# m52363b register map
Vendor: Elmos Semiconductor SE; Series: Integrated Driver; File version: 1.0
CPU: CM23 r1p0, little endian, MPU, no FPU, VTOR, 2 interrupt priority bits, 13 interrupts
Registers are 16-bit, read-write, reset 0x0 unless marked. A register's access mark holds for its fields unless they carry their own. Offsets are from the block's base; [hi:lo] are bit positions; {n}, {i} and the like mark numbered series; 'fields as' and 'values as' point back to an identical list.

## HB — Half bridge control module
Base 0x50000200
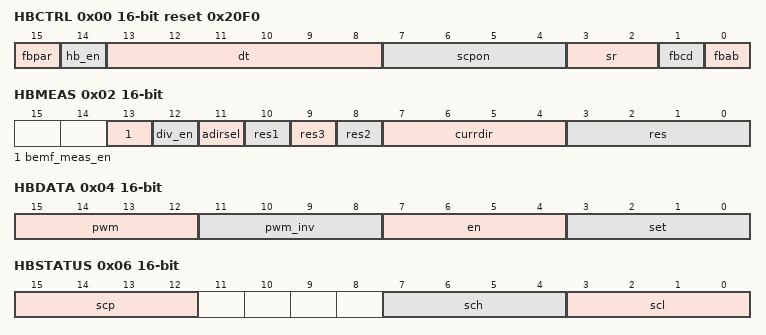
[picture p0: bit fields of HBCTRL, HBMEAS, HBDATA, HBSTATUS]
0x00 HBCTRL reset 0x20F0
  [15] fbpar — fbpar bitfield
  [14] hb_en — hb_en bitfield
  [13:8] dt — dt bitfield
  [7:4] scpon — scpon bitfield
  [3:2] sr — sr bitfield
  [1] fbcd — fbcd bitfield
  [0] fbab — fbab bitfield
0x02 HBMEAS
  [13] bemf_meas_en — bemf_meas_en bitfield
  [12] div_en — div_en bitfield
  [11] adirsel — adirsel bitfield
  [10] res1 — res1 bitfield
  [9] res3 — res3 bitfield
  [8] res2 — res2 bitfield
  [7:4] currdir ro — currdir bitfield
  [3:0] res — res bitfield
0x04 HBDATA
  [15:12] pwm — pwm bitfield
  [11:8] pwm_inv — pwm_inv bitfield
  [7:4] en — en bitfield
  [3:0] set — set bitfield
0x06 HBSTATUS
  [15:12] scp — scp bitfield
  [7:4] sch — sch bitfield
  [3:0] scl — scl bitfield
0x0A HBSCPTMR reset 0x7FF
  [11:0] sc_tmr_val — sc_tmr_val bitfield
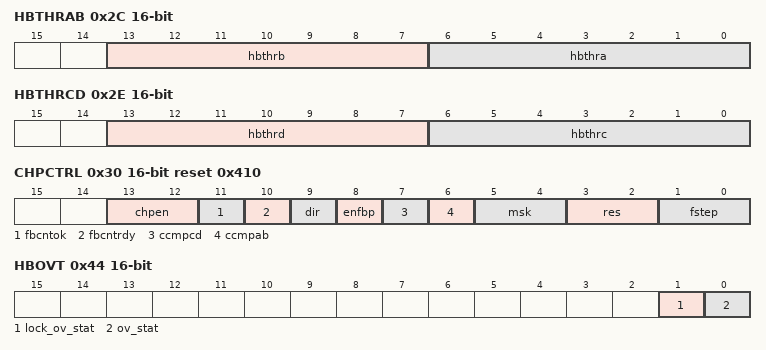
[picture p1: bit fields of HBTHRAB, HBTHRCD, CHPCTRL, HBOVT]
0x2C HBTHRAB
  [13:7] hbthrb — hbthrb bitfield
  [6:0] hbthra — hbthra bitfield
0x2E HBTHRCD
  [13:7] hbthrd — hbthrd bitfield
  [6:0] hbthrc — hbthrc bitfield
0x30 CHPCTRL reset 0x410
  [13:12] chpen — chpen bitfield
  [11] fbcntok ro — fbcntok bitfield
  [10] fbcntrdy ro — fbcntrdy bitfield
  [9] dir — dir bitfield
  [8] enfbp — enfbp bitfield
  [7] ccmpcd ro — ccmpcd bitfield
  [6] ccmpab ro — ccmpab bitfield
  [5:4] msk — msk bitfield
  [3:2] res — res bitfield
  [1:0] fstep — fstep bitfield
0x32 STPCTRL
  [0] stp — stp bitfield
0x34 IDACAB reset 0x1
  [7:0] val — val bitfield
0x36 IDACCD reset 0x1
  [7:0] val — val bitfield
0x38 TONAB ro
  [10:0] val — val bitfield
0x3A TONCD ro
  [10:0] val — val bitfield
0x3C FDEC reset 0x1
  [10:0] val — val bitfield
0x3E CNTFBC ro
  [6:0] val — val bitfield
0x40 HBCTRL1
  [3:0] ds_fasten — ds_fasten bitfield
0x44 HBOVT
  [1] lock_ov_stat — lock_ov_stat bitfield
  [0] ov_stat — ov_stat bitfield
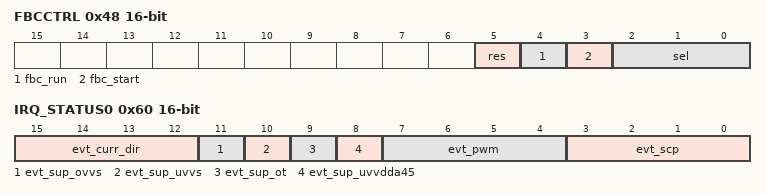
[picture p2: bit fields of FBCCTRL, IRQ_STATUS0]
0x48 FBCCTRL
  [5] res — res bitfield
  [4] fbc_run ro — fbc_run bitfield
  [3] fbc_start — fbc_start bitfield
  [2:0] sel — sel bitfield
0x60 IRQ_STATUS0
  [15:12] evt_curr_dir — evt_curr_dir bitfield
  [11] evt_sup_ovvs — evt_sup_ovvs bitfield
  [10] evt_sup_uvvs — evt_sup_uvvs bitfield
  [9] evt_sup_ot — evt_sup_ot bitfield
  [8] evt_sup_uvvdda45 — evt_sup_uvvdda45 bitfield
  [7:4] evt_pwm — evt_pwm bitfield
  [3:0] evt_scp — evt_scp bitfield
0x62 IRQ_STATUS1
  [0] evt_fbc_rdy — evt_fbc_rdy bitfield
0x64 IRQ_MASK0
  [15:0] mask — mask bitfield
0x66 IRQ_MASK1
  [0] mask — mask bitfield
0x68 IRQ_VENABLE wo reset not defined
  [4:0] vno — vno bitfield
0x6A IRQ_VDISABLE wo reset not defined
  [4:0] vno — vno bitfield
0x6C IRQ_VMAX reset 0x11
  [4:0] vmax — vmax bitfield
0x6E IRQ_VNO reset 0x11
  [4:0] vno — vno bitfield

## PWM — PWM module for half bridge control
Base 0x50000300
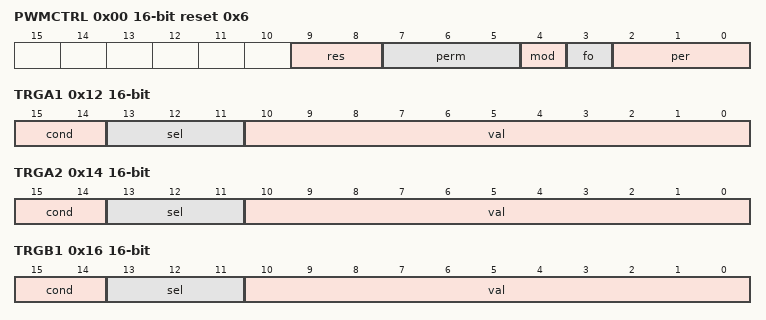
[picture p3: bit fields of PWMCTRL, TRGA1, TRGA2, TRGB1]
0x00 PWMCTRL reset 0x6
  [9:8] res — res bitfield
  [7:5] perm — perm bitfield
  [4] mod — mod bitfield
  [3] fo — fo bitfield
  [2:0] per — per bitfield
0x02 PWMVALA
  [15:5] val — val bitfield
0x04 PWMVALB
  [15:5] val — val bitfield
0x06 PWMVALC
  [15:5] val — val bitfield
0x08 PWMVALD
  [15:5] val — val bitfield
0x0A PWMSHIFTA
  [10:0] val — val bitfield
0x0C PWMSHIFTB
  [10:0] val — val bitfield
0x0E PWMSHIFTC
  [10:0] val — val bitfield
0x10 PWMSHIFTD
  [10:0] val — val bitfield
0x12 TRGA1
  [15:14] cond — cond bitfield
  [13:11] sel — sel bitfield
  [10:0] val — val bitfield
0x14 TRGA2
  fields as TRGA1
0x16 TRGB1
  fields as TRGA1
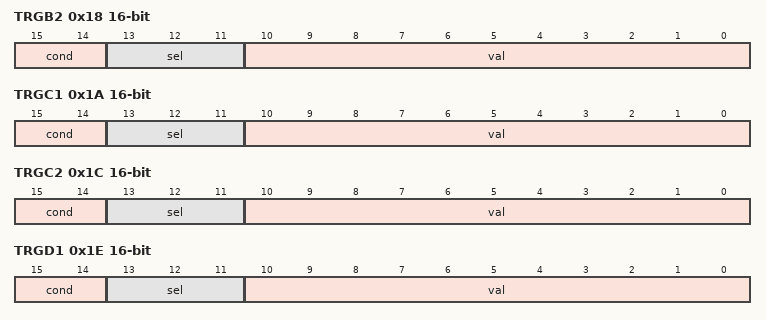
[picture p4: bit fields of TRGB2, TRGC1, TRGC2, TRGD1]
0x18 TRGB2
  fields as TRGA1
0x1A TRGC1
  fields as TRGA1
0x1C TRGC2
  fields as TRGA1
0x1E TRGD1
  fields as TRGA1
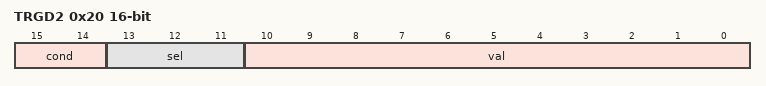
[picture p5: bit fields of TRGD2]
0x20 TRGD2
  fields as TRGA1

## ADC — ADC control module
Base 0x50000400
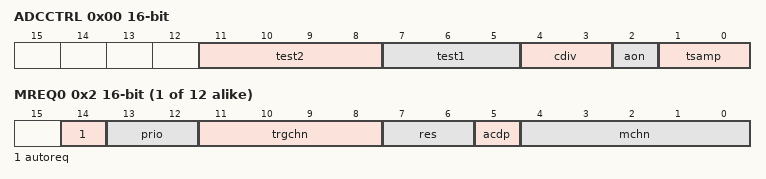
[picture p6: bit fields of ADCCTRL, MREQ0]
0x00 ADCCTRL
  [11:8] test2 — test2 bitfield
  [7:5] test1 — test1 bitfield
  [4:3] cdiv — cdiv bitfield
  [2] aon — aon bitfield
  [1:0] tsamp — tsamp bitfield
{0x2+2i} MREQ{i} (i=0..11)
  [14] autoreq — autoreq bitfield
  [13:12] prio — prio bitfield
  [11:8] trgchn — trgchn bitfield
  [7:6] res — res bitfield
  [5] acdp — acdp bitfield
  [4:0] mchn — mchn bitfield
{0x1A+2i} MVAL{i} ro (i=0..11)
  [15:3] mval — mval bitfield
0x60 IRQ_STATUS
  [11:0] evt_meas — evt_meas bitfield
0x64 IRQ_MASK
  [11:0] mask — mask bitfield
0x68 IRQ_VENABLE wo reset not defined
  [3:0] vno — vno bitfield
0x6A IRQ_VDISABLE wo reset not defined
  [3:0] vno — vno bitfield
0x6C IRQ_VMAX reset 0xC
  [3:0] vmax — vmax bitfield
0x6E IRQ_VNO reset 0xC
  [3:0] vno — vno bitfield
